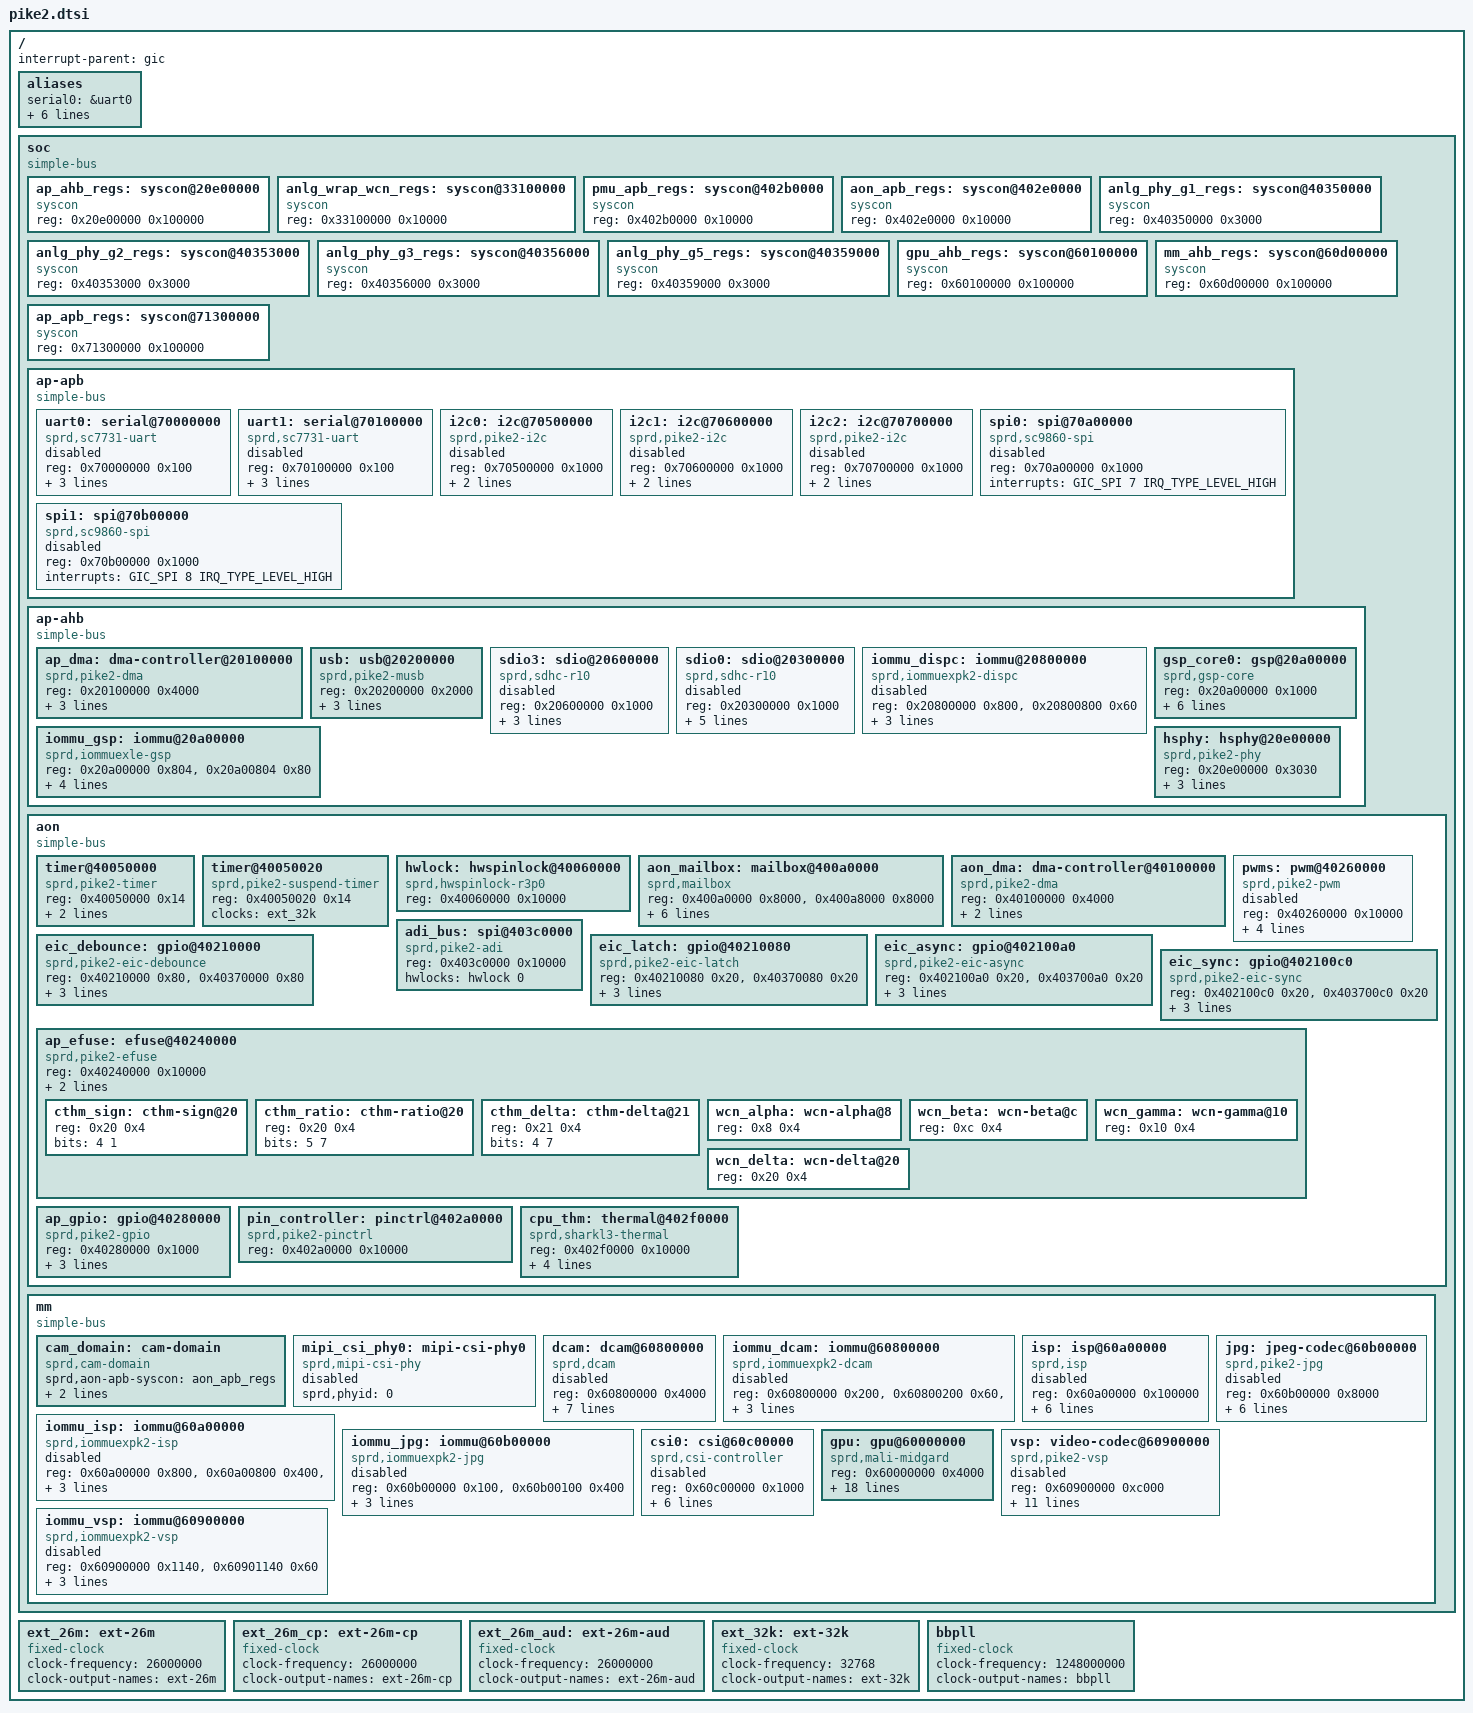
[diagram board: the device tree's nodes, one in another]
/*
 * Spreadtrum pike2 platform DTS file
 *
 * Copyright (C) 2019, Spreadtrum Communications Inc.
 *
 * This file is licensed under a dual GPLv2 or X11 license.
 */

#include <dt-bindings/interrupt-controller/arm-gic.h>
#include <dt-bindings/soc/sprd,pike2-regs.h>
#include <dt-bindings/soc/sprd,pike2-mask.h>

/ {
	interrupt-parent = <&gic>;
	#address-cells = <1>;
	#size-cells = <1>;

	aliases {
		serial0 = &uart0;
		serial1 = &uart1;
		i2c0 = &i2c0;
		i2c1 = &i2c1;
		i2c2 = &i2c2;
		spi0 = &spi0;
		spi1 = &spi1;
	};

	soc: soc {
		compatible = "simple-bus";
		#address-cells = <1>;
		#size-cells = <1>;
		ranges;

		ap_ahb_regs: syscon@20e00000 {
			compatible = "syscon";
			#syscon-cells = <2>;
			reg = <0x20e00000 0x100000>;
		};

		anlg_wrap_wcn_regs: syscon@33100000 {
			compatible = "syscon";
			#syscon-cells = <2>;
			reg = <0x33100000 0x10000>;
		};

		pmu_apb_regs: syscon@402b0000 {
			compatible = "syscon";
			#syscon-cells = <2>;
			reg = <0x402b0000 0x10000>;
		};

		aon_apb_regs: syscon@402e0000 {
			compatible = "syscon";
			#syscon-cells = <2>;
			reg = <0x402e0000 0x10000>;
		};

		anlg_phy_g1_regs: syscon@40350000 {
			compatible = "syscon";
			#syscon-cells = <2>;
			reg = <0x40350000 0x3000>;
		};

		anlg_phy_g2_regs: syscon@40353000 {
			compatible = "syscon";
			#syscon-cells = <2>;
			reg = <0x40353000 0x3000>;
		};

		anlg_phy_g3_regs: syscon@40356000 {
			compatible = "syscon";
			#syscon-cells = <2>;
			reg = <0x40356000 0x3000>;
		};

		anlg_phy_g5_regs: syscon@40359000 {
			compatible = "syscon";
			#syscon-cells = <2>;
			reg = <0x40359000 0x3000>;
		};

		gpu_ahb_regs: syscon@60100000 {
			compatible = "syscon";
			#syscon-cells = <2>;
			reg = <0x60100000 0x100000>;
		};

		mm_ahb_regs: syscon@60d00000 {
			compatible = "syscon";
			#syscon-cells = <2>;
			reg = <0x60d00000 0x100000>;
		};

		ap_apb_regs: syscon@71300000 {
			compatible = "syscon";
			#syscon-cells = <2>;
			reg = <0x71300000 0x100000>;
		};

		ap-apb {
			compatible = "simple-bus";
			#address-cells = <1>;
			#size-cells = <1>;
			ranges;

			uart0: serial@70000000 {
				compatible = "sprd,sc7731-uart",
					     "sprd,sc9836-uart";
				reg = <0x70000000 0x100>;
				interrupts = <GIC_SPI 2 IRQ_TYPE_LEVEL_HIGH>;
				clock-names = "enable", "uart", "source";
				clocks = <&apapb_gate CLK_UART0_EB>,
					 <&ap_clk CLK_AP_UART0>,
					 <&ext_26m>;
				status = "disabled";
			};

			uart1: serial@70100000 {
				compatible = "sprd,sc7731-uart",
					     "sprd,sc9836-uart";
				reg = <0x70100000 0x100>;
				interrupts = <GIC_SPI 3 IRQ_TYPE_LEVEL_HIGH>;
				clock-names = "enable", "uart", "source";
				clocks = <&apapb_gate CLK_UART1_EB>,
					 <&ap_clk CLK_AP_UART1>,
					 <&ext_26m>;
				status = "disabled";
			};

			i2c0: i2c@70500000 {
				compatible = "sprd,pike2-i2c";
				reg = <0x70500000 0x1000>;
				interrupts = <GIC_SPI 11 IRQ_TYPE_LEVEL_HIGH>;
				clock-names = "enable", "i2c", "source";
				clock-frequency = <100000>;
				#address-cells = <1>;
				#size-cells = <0>;
				status = "disabled";
			};

			i2c1: i2c@70600000 {
				compatible = "sprd,pike2-i2c";
				reg = <0x70600000 0x1000>;
				interrupts = <GIC_SPI 12 IRQ_TYPE_LEVEL_HIGH>;
				clock-names = "enable", "i2c", "source";
				clock-frequency = <100000>;
				#address-cells = <1>;
				#size-cells = <0>;
				status = "disabled";
			};

			i2c2: i2c@70700000 {
				compatible = "sprd,pike2-i2c";
				reg = <0x70700000 0x1000>;
				interrupts = <GIC_SPI 13 IRQ_TYPE_LEVEL_HIGH>;
				clock-names = "enable", "i2c", "source";
				clock-frequency = <100000>;
				#address-cells = <1>;
				#size-cells = <0>;
				status = "disabled";
			};

			spi0: spi@70a00000{
				compatible = "sprd,sc9860-spi",
					"sprd,pike2-spi";
				reg = <0x70a00000 0x1000>;
				interrupts = <GIC_SPI 7 IRQ_TYPE_LEVEL_HIGH>;
				#address-cells = <1>;
				#size-cells = <0>;
				status = "disabled";
			};

			spi1: spi@70b00000{
				compatible = "sprd,sc9860-spi",
					"sprd,pike2-spi";
				reg = <0x70b00000 0x1000>;
				interrupts = <GIC_SPI 8 IRQ_TYPE_LEVEL_HIGH>;
				#address-cells = <1>;
				#size-cells = <0>;
				status = "disabled";
			};
		};

		ap-ahb {
			compatible = "simple-bus";
			#address-cells = <1>;
			#size-cells = <1>;
			ranges;

			ap_dma: dma-controller@20100000 {
				compatible = "sprd,pike2-dma";
				reg = <0x20100000 0x4000>;
				interrupts = <GIC_SPI 50 IRQ_TYPE_LEVEL_HIGH>;
				#dma-cells = <1>;
				#dma-channels = <28>;
				clock-names = "enable";
				clocks = <&apahb_gate CLK_DMA_EB>;
			};

			usb: usb@20200000 {
				compatible  = "sprd,pike2-musb";
				reg = <0x20200000 0x2000>;
				interrupts = <GIC_SPI 55 IRQ_TYPE_LEVEL_HIGH>;
				interrupt-names = "mc";
				clocks = <&apahb_gate CLK_OTG_EB>;
				clock-names = "core_clk";
				usb-phy = <&hsphy>;
				phy-names = "usb";
			};

			sdio3: sdio@20600000 {
				compatible  = "sprd,sdhc-r10";
				reg = <0x20600000 0x1000>;
				interrupts = <GIC_SPI 60 IRQ_TYPE_LEVEL_HIGH>;
				clock-names = "sdio_clk","sdio_clk_source",
					      "sdio_ahb_enable";
				clocks = <&aon_clk CLK_EMMC_2X>,
					 <&pll CLK_TWPLL_384M>,
					 <&apahb_gate CLK_EMMC_EB>;
				status = "disabled";
			};

			sdio0: sdio@20300000 {
				compatible  = "sprd,sdhc-r10";
				reg = <0x20300000 0x1000>;
				interrupts = <GIC_SPI 57 IRQ_TYPE_LEVEL_HIGH>;
				clock-names = "sdio_clk","sdio_clk_source",
					      "sdio_ahb_enable","sdio_1x_eb",
					      "sdio_2x_eb";
				clocks = <&aon_clk CLK_SDIO0_2X>,
					 <&pll CLK_TWPLL_384M>,
					 <&apahb_gate CLK_SDIO0_EB>,
					 <&aonapb_gate CLK_SDIO0_1X_EB>,
					 <&aonapb_gate CLK_SDIO0_2X_EB>;
				status = "disabled";
			};

			iommu_dispc: iommu@20800000 {
				compatible = "sprd,iommuexpk2-dispc";
				reg = <0x20800000 0x800>,
				      <0x20800800 0x60>;
				iova-base = <0x30000000>;
				iova-size = <0x08000000>;
				reg_name = "mmu_interrupt_reg","mmu_reg";
				status = "disabled";
				#iommu-cells = <0>;
			};

			gsp_core0: gsp@20a00000 {
				compatible = "sprd,gsp-core";
				reg = <0x20a00000 0x1000>;
				core-id = <0>;
				kcfg-num = <16>;
				interrupts = <GIC_SPI 51 IRQ_TYPE_LEVEL_HIGH>;
				iommus = <&iommu_gsp>;
				clock-names = "clk_gsp",
					"clk_gsp_parent",
					"clk_gsp_eb";
				clocks = <&ap_clk CLK_GSP>,
					<&pll CLK_TWPLL_384M>,
					<&apahb_gate CLK_GSP_EB>;
			};

			iommu_gsp: iommu@20a00000 {
				compatible = "sprd,iommuexle-gsp";
				reg = <0x20a00000 0x804>,
					<0x20a00804 0x80>;
				iova-base = <0x20000000>;
				iova-size = <0x10000000>;
				reg_name = "mmu_interrupt_reg","mmu_reg",
					"iova pool";
				status = "ok";
				#iommu-cells = <0>;
			};

			hsphy: hsphy@20e00000 {
				compatible = "sprd,pike2-phy";
				reg = <0x20e00000 0x3030>;
				reg-names = "phy_glb_regs";
				sprd,syscon-enable = <&aon_apb_regs>;
				sprd,tune-value = <0x0005af33>;
				sprd,vdd-voltage = <3300000>;
				#phy-cells = <0>;
			};
		};

		aon {
			compatible = "simple-bus";
			#address-cells = <1>;
			#size-cells = <1>;
			ranges;

			timer@40050000 {
				compatible = "sprd,pike2-timer";
				reg = <0x40050000 0x14>;
				interrupts = <GIC_SPI 28 IRQ_TYPE_LEVEL_HIGH>;
				clocks = <&ext_32k>;
			};

			timer@40050020 {
				compatible = "sprd,pike2-suspend-timer";
				reg = <0x40050020 0x14>;
				clocks = <&ext_32k>;
			};

			hwlock: hwspinlock@40060000{
				compatible = "sprd,hwspinlock-r3p0";
				reg = <0x40060000 0x10000>;
				#hwlock-cells = <1>;
			};

			aon_mailbox: mailbox@400a0000 {
				compatible = "sprd,mailbox";
				reg = <0x400a0000 0x8000>,
				      <0x400a8000 0x8000>;
				syscons = <&aon_apb_regs 0x4 0x200000>;
				syscon-names = "clk";
				interrupts = <GIC_SPI 68 IRQ_TYPE_LEVEL_HIGH>,
					     <GIC_SPI 69 IRQ_TYPE_LEVEL_HIGH>;
				sprd,core-cnt = <6>;
				sprd,version = <0x102>;
			};

			aon_dma: dma-controller@40100000 {
				compatible = "sprd,pike2-dma";
				reg = <0x40100000 0x4000>;
				#dma-cells = <1>;
				#dma-channels = <13>;
				clock-names = "enable";
				clocks = <&aonapb_gate CLK_AON_DMA_EB>;
			};

			pwms: pwm@40260000 {
				compatible = "sprd,pike2-pwm", "sprd,sharkl5-pwm";
				reg = <0x40260000 0x10000>;
				clock-names = "clk_parent",
					"clk_pwm0", "clk_pwm0_eb",
					"clk_pwm1", "clk_pwm1_eb",
					"clk_pwm2", "clk_pwm2_eb";
				clocks = <&ext_26m>,
					<&aon_clk CLK_PWM0>,
					<&aonapb_gate CLK_PWM0_EB>,
					<&aon_clk CLK_PWM1>,
					<&aonapb_gate CLK_PWM1_EB>,
					<&aon_clk CLK_PWM2>,
					<&aonapb_gate CLK_PWM2_EB>;
				#pwm-cells = <2>;
				status = "disabled";
			};

			adi_bus: spi@403c0000 {
				compatible = "sprd,pike2-adi";
				reg = <0x403c0000 0x10000>;
				hwlocks = <&hwlock 0>;
				#address-cells = <1>;
				#size-cells = <0>;
			};

			eic_debounce: gpio@40210000 {
				compatible = "sprd,pike2-eic-debounce";
				reg = <0x40210000 0x80>,
				      <0x40370000 0x80>;
				gpio-controller;
				#gpio-cells = <2>;
				interrupt-controller;
				#interrupt-cells = <2>;
				interrupts = <GIC_SPI 37 IRQ_TYPE_LEVEL_HIGH>;
			};

			eic_latch: gpio@40210080 {
				compatible = "sprd,pike2-eic-latch";
				reg = <0x40210080 0x20>,
				      <0x40370080 0x20>;
				gpio-controller;
				#gpio-cells = <2>;
				interrupt-controller;
				#interrupt-cells = <2>;
				interrupts = <GIC_SPI 37 IRQ_TYPE_LEVEL_HIGH>;
			};

			eic_async: gpio@402100a0 {
				compatible = "sprd,pike2-eic-async";
				reg = <0x402100a0 0x20>,
				      <0x403700a0 0x20>;
				gpio-controller;
				#gpio-cells = <2>;
				interrupt-controller;
				#interrupt-cells = <2>;
				interrupts = <GIC_SPI 37 IRQ_TYPE_LEVEL_HIGH>;
			};

			eic_sync: gpio@402100c0 {
				compatible = "sprd,pike2-eic-sync";
				reg = <0x402100c0 0x20>,
				      <0x403700c0 0x20>;
				gpio-controller;
				#gpio-cells = <2>;
				interrupt-controller;
				#interrupt-cells = <2>;
				interrupts = <GIC_SPI 37 IRQ_TYPE_LEVEL_HIGH>;
			};

			ap_efuse: efuse@40240000 {
				compatible = "sprd,pike2-efuse";
				reg = <0x40240000 0x10000>;
				clock-names = "enable";
				hwlocks = <&hwlock 8>;
				clocks = <&aonapb_gate CLK_EFUSE_EB>;

				cthm_sign: cthm-sign@20{
					reg = <0x20 0x4>;
					bits = <4 1>;
				};

				cthm_ratio: cthm-ratio@20{
					reg = <0x20 0x4>;
					bits = <5 7>;
				};

				cthm_delta: cthm-delta@21{
					reg = <0x21 0x4>;
					bits = <4 7>;
				};

				wcn_alpha: wcn-alpha@8 {
					reg = <0x8 0x4>;
				};

				wcn_beta: wcn-beta@c {
					reg = <0xc 0x4>;
				};

				wcn_gamma: wcn-gamma@10 {
					reg = <0x10 0x4>;
				};

				wcn_delta: wcn-delta@20 {
					reg = <0x20 0x4>;
				};
			};

			ap_gpio: gpio@40280000 {
				compatible = "sprd,pike2-gpio";
				reg = <0x40280000 0x1000>;
				gpio-controller;
				#gpio-cells = <2>;
				interrupt-controller;
				#interrupt-cells = <2>;
				interrupts = <GIC_SPI 35 IRQ_TYPE_LEVEL_HIGH>;
			};

			pin_controller: pinctrl@402a0000 {
				compatible = "sprd,pike2-pinctrl";
				reg = <0x402a0000 0x10000>;
			};

			cpu_thm: thermal@402f0000 {
				compatible = "sprd,sharkl3-thermal","sprd,pike2-thermal";
				reg = <0x402f0000 0x10000>;
				clock-names = "enable";
				clocks = <&aonapb_gate CLK_THM_EB>;
				#thermal-sensor-cells = <1>;
				nvmem-cells = <&cthm_sign>, <&cthm_ratio>, <&cthm_delta>;
				nvmem-cell-names = "thm_sign_cal", "thm_ratio_cal", "thm_delta_cal";
			};
		};

		mm {
			compatible = "simple-bus";
			#address-cells = <1>;
			#size-cells = <1>;
			ranges;

			cam_domain: cam-domain {
				compatible = "sprd,cam-domain";
				sprd,aon-apb-syscon = <&aon_apb_regs>;
				sprd,cam-ahb-syscon = <&ap_ahb_regs>;
				sprd,syscon-pmu-apb = <&pmu_apb_regs>;
			};

			mipi_csi_phy0: mipi-csi-phy0 {
				compatible = "sprd,mipi-csi-phy";
				sprd,phyid = <0>;
				status = "disabled";
			};

			dcam: dcam@60800000 {
				compatible = "sprd,dcam";
				reg = <0x60800000 0x4000>;
				interrupts = <GIC_SPI 45 IRQ_TYPE_LEVEL_HIGH>;
				sprd,cam-ahb-syscon = <&aon_apb_regs>;
				sprd,aon-apb-syscon = <&aon_apb_regs>;
				sprd,syscon-pmu-apb = <&pmu_apb_regs>;
				sprd,isp = <&isp>;
				sprd,dcam-count = <1>;
				iommus = <&iommu_dcam>;
				status = "disable";
			};

			iommu_dcam: iommu@60800000 {
				compatible = "sprd,iommuexpk2-dcam";
				reg = <0x60800000 0x200>,
					<0x60800200 0x60>,
					<0x40000000 0x10000000>;
				reg_name = "mmu_interrupt_reg","mmu_reg",
						"iova pool";
				status = "disabled";
				#iommu-cells = <0>;
			};

			isp: isp@60a00000 {
				compatible = "sprd,isp";
				reg = <0x60a00000 0x100000>;
				interrupts = <GIC_SPI 44 IRQ_TYPE_LEVEL_HIGH>,
					<GIC_SPI 125 IRQ_TYPE_LEVEL_HIGH>;
				sprd,cam-ahb-syscon = <&ap_ahb_regs>;
				sprd,aon-apb-syscon = <&aon_apb_regs>;
				sprd,isp-count = <1>;
				iommus = <&iommu_isp>;
				status = "disable";
			};

			iommu_isp: iommu@60a00000 {
				compatible = "sprd,iommuexpk2-isp";
				reg = <0x60a00000 0x800>,
					<0x60a00800 0x400>,
					<0x50000000 0x10000000>;
				reg_name = "mmu_interrupt_reg","mmu_reg",
					"iova pool";
				status = "disabled";
				#iommu-cells = <0>;
			};

			jpg: jpeg-codec@60b00000{
				compatible = "sprd,pike2-jpg";
				reg = <0x60b00000 0x8000>;
				interrupts = <GIC_SPI 42 IRQ_TYPE_LEVEL_HIGH>;
				syscons = <&mm_ahb_regs  REG_AP_AHB_AHB_RST
					MASK_MM_AHB_JPG_SOFT_RST>,
					<&aon_apb_regs
					REG_AON_APB_APB_EB0
					MASK_AON_APB_MM_EB>;
				syscon-names = "reset",
					"aon_apb_eb";
				iommus = <&iommu_jpg>;
				status = "disabled";
			};

			iommu_jpg: iommu@60b00000 {
				compatible = "sprd,iommuexpk2-jpg";
				reg = <0x60b00000 0x100>,
				<0x60b00100 0x400>;
				iova-base = <0x70000000>;
				iova-size = <0x10000000>;
				reg_name = "mmu_interrupt_reg","mmu_reg";
				status = "disabled";
				#iommu-cells = <0>;
			};

			csi0: csi@60c00000 {
				compatible = "sprd,csi-controller";
				reg = <0x60c00000 0x1000>;
				interrupts = <GIC_SPI 40 IRQ_TYPE_LEVEL_HIGH>,
					<GIC_SPI 41 IRQ_TYPE_LEVEL_HIGH>;
				sprd,cam-ahb-syscon = <&ap_ahb_regs>;
				sprd,ana-apb-syscon = <&aon_apb_regs>;
				sprd,csi-id = <0>;
				sprd,ip-version = <0x100>;
				status = "disable";
			};

			gpu: gpu@60000000 {
				compatible = "sprd,mali-midgard";
				reg = <0x60000000 0x4000>;
				gpu-supply = <&vddcore>;
				syscons = <&pmu_apb_regs
					REG_PMU_APB_PD_GPU_TOP_CFG
					MASK_PMU_APB_PD_GPU_TOP_FORCE_SHUTDOWN>;
				syscon-names = "top_force_shutdown";

				interrupts = <GIC_SPI 39 IRQ_TYPE_LEVEL_HIGH>,
					<GIC_SPI 39 IRQ_TYPE_LEVEL_HIGH>,
					<GIC_SPI 39 IRQ_TYPE_LEVEL_HIGH>;
				interrupt-names = "JOB",
					"MMU",
					"GPU";

				operating-points = <
					/* kHz    uV */
					153600    900000
					256000    900000
					384000    900000
					512000    900000
					533000    900000
					600000    1000000
					>;

				sprd,dfs-lists = <
					/* kHz  uV      idx div */
					153600  900000   2    1
					256000  900000   4    1
					384000  900000   6    1
					512000  900000   7    1
					533000  900000   8    1
					600000  1000000  8    1
					>;

				sprd,dfs-default = <1>;
				sprd,dfs-scene-extreme = <3>;
				sprd,dfs-scene-high = <2>;
				sprd,dfs-scene-medium = <1>;
				sprd,dfs-scene-low = <0>;
				sprd,dfs-range-max = <5>;
				sprd,dfs-range-min = <0>;
			};

			vsp: video-codec@60900000{
				compatible = "sprd,pike2-vsp";
				reg = <0x60900000 0xc000>;
				interrupts = <GIC_SPI 43 IRQ_TYPE_LEVEL_HIGH>;
				syscons = <&mm_ahb_regs  REG_AP_AHB_AHB_RST
					MASK_MM_AHB_VSP_SOFT_RST>,
					<&pmu_apb_regs
					REG_PMU_APB_PD_MM_TOP_CFG
					MASK_PMU_APB_PD_MM_TOP_FORCE_SHUTDOWN>,
					<&pmu_apb_regs
					REG_PMU_APB_PD_MM_TOP_CFG
					MASK_PMU_APB_PD_MM_TOP_AUTO_SHUTDOWN_EN>,
					<&pmu_apb_regs
					REG_PMU_APB_PWR_STATUS0_DBG
					MASK_PMU_APB_PD_MM_TOP_STATE>,
					<&aon_apb_regs
					REG_AON_APB_APB_EB0
					MASK_AON_APB_MM_EB>;
				syscon-names = "reset",
					"pmu_vsp_force_shutdown",
					"pmu_vsp_auto_shutdown",
					"pmu_pwr_status",
					"vsp_domain_eb";
				iommus = <&iommu_vsp>;
				status = "disabled";
			};

			iommu_vsp: iommu@60900000 {
				compatible = "sprd,iommuexpk2-vsp";
				reg = <0x60900000 0x1140>,
				<0x60901140 0x60>;
				iova-base = <0x20000000>;
				iova-size = <0x10000000>;
				reg_name = "mmu_interrupt_reg","mmu_reg";
				status = "disabled";
				#iommu-cells = <0>;
			};
		};
	};

	ext_26m: ext-26m {
		compatible = "fixed-clock";
		#clock-cells = <0>;
		clock-frequency = <26000000>;
		clock-output-names = "ext-26m";
	};

	ext_26m_cp: ext-26m-cp {
		compatible = "fixed-clock";
		#clock-cells = <0>;
		clock-frequency = <26000000>;
		clock-output-names = "ext-26m-cp";
	};

	ext_26m_aud: ext-26m-aud {
		compatible = "fixed-clock";
		#clock-cells = <0>;
		clock-frequency = <26000000>;
		clock-output-names = "ext-26m-aud";
	};

	ext_32k: ext-32k {
		compatible = "fixed-clock";
		#clock-cells = <0>;
		clock-frequency = <32768>;
		clock-output-names = "ext-32k";
	};

	bbpll: bbpll {
		compatible = "fixed-clock";
		#clock-cells = <0>;
		clock-frequency = <1248000000>;
		clock-output-names = "bbpll";
	};
};

